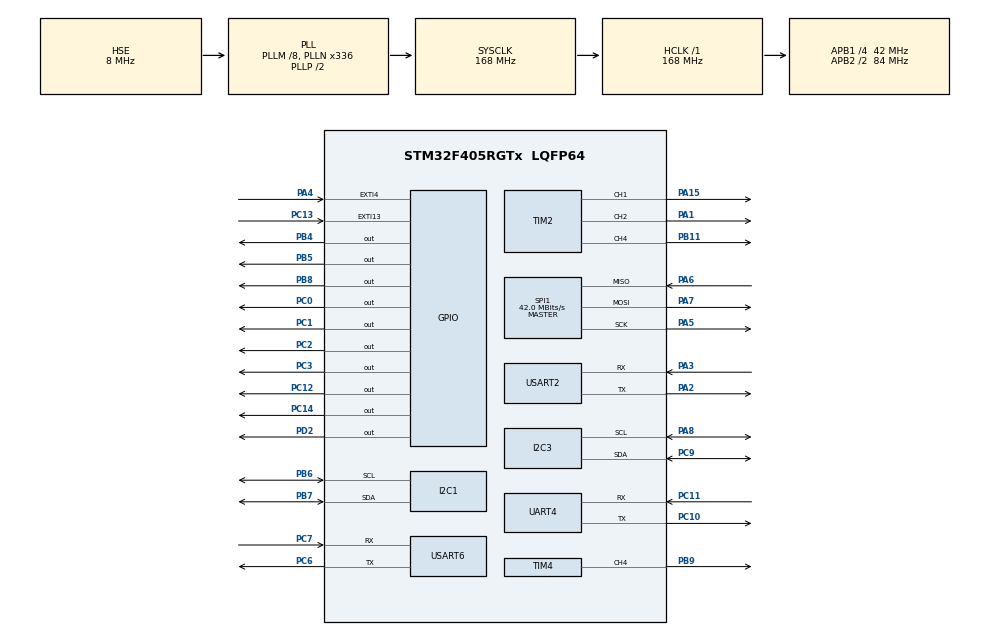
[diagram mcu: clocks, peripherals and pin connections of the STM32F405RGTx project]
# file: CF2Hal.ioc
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Mcu.Family=STM32F4
Mcu.Name=STM32F405RGTx
Mcu.Package=LQFP64
NVIC.PriorityGroup=NVIC_PRIORITYGROUP_4
PA1.Signal=S_TIM2_CH2
PA13.Mode=Trace_Asynchronous_SW
PA13.Signal=SYS_JTMS-SWDIO
PA14.Mode=Trace_Asynchronous_SW
PA14.Signal=SYS_JTCK-SWCLK
PA15.Signal=S_TIM2_CH1_ETR
PA2.Mode=Asynchronous
PA2.Signal=USART2_TX
PA3.Mode=Asynchronous
PA3.Signal=USART2_RX
PA4.Signal=GPXTI4
PA5.Mode=Full_Duplex_Master
PA5.Signal=SPI1_SCK
PA6.Mode=Full_Duplex_Master
PA6.Signal=SPI1_MISO
PA7.Mode=Full_Duplex_Master
PA7.Signal=SPI1_MOSI
PA8.Mode=I2C
PA8.Signal=I2C3_SCL
PB11.Signal=S_TIM2_CH4
PB3.Mode=Trace_Asynchronous_SW
PB3.Signal=SYS_JTDO-SWO
PB4.Signal=GPIO_Output
PB5.Signal=GPIO_Output
PB6.Mode=I2C
PB6.Signal=I2C1_SCL
PB7.Mode=I2C
PB7.Signal=I2C1_SDA
PB8.Signal=GPIO_Output
PB9.Signal=S_TIM4_CH4
PC0.Signal=GPIO_Output
PC1.Signal=GPIO_Output
PC10.Mode=Asynchronous
PC10.Signal=UART4_TX
PC11.Mode=Asynchronous
PC11.Signal=UART4_RX
PC12.Signal=GPIO_Output
PC13-ANTI_TAMP.Signal=GPXTI13
PC14-OSC32_IN.Signal=GPIO_Output
PC2.Signal=GPIO_Output
PC3.Signal=GPIO_Output
PC6.Mode=Asynchronous
PC6.Signal=USART6_TX
PC7.Mode=Asynchronous
PC7.Signal=USART6_RX
PC9.Mode=I2C
PC9.Signal=I2C3_SDA
PD2.Signal=GPIO_Output
PH0-OSC_IN.Mode=HSE-External-Oscillator
PH0-OSC_IN.Signal=RCC_OSC_IN
PH1-OSC_OUT.Mode=HSE-External-Oscillator
PH1-OSC_OUT.Signal=RCC_OSC_OUT
ProjectManager.HeapSize=0x16000
ProjectManager.StackSize=0x5000
ProjectManager.TargetToolchain=Makefile
RCC.48MHZClocksFreq_Value=84000000
RCC.AHBFreq_Value=168000000
RCC.APB1CLKDivider=RCC_HCLK_DIV4
RCC.APB1Freq_Value=42000000
RCC.APB1TimFreq_Value=84000000
RCC.APB2CLKDivider=RCC_HCLK_DIV2
RCC.APB2Freq_Value=84000000
RCC.APB2TimFreq_Value=168000000
RCC.CortexFreq_Value=21000000
RCC.Cortex_Div=SYSTICK_CLKSOURCE_HCLK_DIV8
RCC.HCLKFreq_Value=168000000
RCC.HSE_VALUE=8000000
RCC.HSI_VALUE=16000000
RCC.LSE_VALUE=32768
RCC.PLLM=8
RCC.PLLN=336
RCC.PLLSourceVirtual=RCC_PLLSOURCE_HSE
RCC.SYSCLKFreq_VALUE=168000000
RCC.SYSCLKSource=RCC_SYSCLKSOURCE_PLLCLK
RCC.VCOOutputFreq_Value=336000000
SH.S_TIM2_CH1_ETR.0=TIM2_CH1,PWM Generation1 CH1
SH.S_TIM2_CH2.0=TIM2_CH2,PWM Generation2 CH2
SH.S_TIM2_CH4.0=TIM2_CH4,PWM Generation4 CH4
SH.S_TIM4_CH4.0=TIM4_CH4,PWM Generation4 CH4
SPI1.BaudRatePrescaler=SPI_BAUDRATEPRESCALER_2
SPI1.CalculateBaudRate=42.0 MBits/s
SPI1.Direction=SPI_DIRECTION_2LINES
SPI1.Mode=SPI_MODE_MASTER
SPI1.VirtualType=VM_MASTER
TIM2.Channel-PWM\ Generation1\ CH1=TIM_CHANNEL_1
TIM2.Channel-PWM\ Generation2\ CH2=TIM_CHANNEL_2
TIM2.Channel-PWM\ Generation4\ CH4=TIM_CHANNEL_4
TIM4.Channel-PWM\ Generation4\ CH4=TIM_CHANNEL_4
UART4.VirtualMode=Asynchronous
USART2.VirtualMode=VM_ASYNC
USART6.VirtualMode=VM_ASYNC
board=custom

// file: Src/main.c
/**
  ******************************************************************************
  * @file           : main.c
  * @brief          : Main program body
  ******************************************************************************
  ** This notice applies to any and all portions of this file
  * that are not between comment pairs USER CODE BEGIN and
  * USER CODE END. Other portions of this file, whether
  * inserted by the user or by software development tools
  * are owned by their respective copyright owners.
  *
  * COPYRIGHT(c) 2019 STMicroelectronics
  *
  * Redistribution and use in source and binary forms, with or without modification,
  * are permitted provided that the following conditions are met:
  *   1. Redistributions of source code must retain the above copyright notice,
  *      this list of conditions and the following disclaimer.
  *   2. Redistributions in binary form must reproduce the above copyright notice,
  *      this list of conditions and the following disclaimer in the documentation
  *      and/or other materials provided with the distribution.
  *   3. Neither the name of STMicroelectronics nor the names of its contributors
  *      may be used to endorse or promote products derived from this software
  *      without specific prior written permission.
  *
  * THIS SOFTWARE IS PROVIDED BY THE COPYRIGHT HOLDERS AND CONTRIBUTORS "AS IS"
  * AND ANY EXPRESS OR IMPLIED WARRANTIES, INCLUDING, BUT NOT LIMITED TO, THE
  * IMPLIED WARRANTIES OF MERCHANTABILITY AND FITNESS FOR A PARTICULAR PURPOSE ARE
  * DISCLAIMED. IN NO EVENT SHALL THE COPYRIGHT HOLDER OR CONTRIBUTORS BE LIABLE
  * FOR ANY DIRECT, INDIRECT, INCIDENTAL, SPECIAL, EXEMPLARY, OR CONSEQUENTIAL
  * DAMAGES (INCLUDING, BUT NOT LIMITED TO, PROCUREMENT OF SUBSTITUTE GOODS OR
  * SERVICES; LOSS OF USE, DATA, OR PROFITS; OR BUSINESS INTERRUPTION) HOWEVER
  * CAUSED AND ON ANY THEORY OF LIABILITY, WHETHER IN CONTRACT, STRICT LIABILITY,
  * OR TORT (INCLUDING NEGLIGENCE OR OTHERWISE) ARISING IN ANY WAY OUT OF THE USE
  * OF THIS SOFTWARE, EVEN IF ADVISED OF THE POSSIBILITY OF SUCH DAMAGE.
  *
  ******************************************************************************
  */
#include "main.h"
#include "stm32f4xx_hal.h"

I2C_HandleTypeDef hi2c1;
I2C_HandleTypeDef hi2c3;

SPI_HandleTypeDef hspi1;

TIM_HandleTypeDef htim2;
TIM_HandleTypeDef htim4;

UART_HandleTypeDef huart4;
UART_HandleTypeDef huart2;
UART_HandleTypeDef huart6;

/* USER CODE BEGIN PV */
/* Private variables ---------------------------------------------------------*/

/* USER CODE END PV */

void SystemClock_Config(void);
static void MX_GPIO_Init(void);
static void MX_TIM2_Init(void);
static void MX_TIM4_Init(void);
static void MX_I2C1_Init(void);
static void MX_I2C3_Init(void);
static void MX_USART6_UART_Init(void);
static void MX_UART4_Init(void);
static void MX_USART2_UART_Init(void);
static void MX_SPI1_Init(void);

void HAL_TIM_MspPostInit(TIM_HandleTypeDef *htim);

/* USER CODE BEGIN PFP */
/* Private function prototypes -----------------------------------------------*/

/* USER CODE END PFP */

/* USER CODE BEGIN 0 */

void fsw_main(void);

/* USER CODE END 0 */

int main(void)
{

  /* MCU Configuration----------------------------------------------------------*/

  /* Reset of all peripherals, Initializes the Flash interface and the Systick. */
  HAL_Init();

  /* Configure the system clock */
  SystemClock_Config();

  /* Initialize all configured peripherals */
  MX_GPIO_Init();
  MX_TIM2_Init();
  MX_TIM4_Init();
  MX_I2C1_Init();
  MX_I2C3_Init();
  MX_USART6_UART_Init();
  MX_UART4_Init();
  MX_USART2_UART_Init();
  MX_SPI1_Init();

  /* USER CODE BEGIN 3 */
  fsw_main();

  /* USER CODE END 3 */

}

void SystemClock_Config(void)
{

  RCC_OscInitTypeDef RCC_OscInitStruct;
  RCC_ClkInitTypeDef RCC_ClkInitStruct;

    /**Configure the main internal regulator output voltage
    */
  __HAL_RCC_PWR_CLK_ENABLE();

  __HAL_PWR_VOLTAGESCALING_CONFIG(PWR_REGULATOR_VOLTAGE_SCALE1);

    /**Initializes the CPU, AHB and APB busses clocks
    */
  RCC_OscInitStruct.OscillatorType = RCC_OSCILLATORTYPE_HSE;
  RCC_OscInitStruct.HSEState = RCC_HSE_ON;
  RCC_OscInitStruct.PLL.PLLState = RCC_PLL_ON;
  RCC_OscInitStruct.PLL.PLLSource = RCC_PLLSOURCE_HSE;
  RCC_OscInitStruct.PLL.PLLM = 8;
  RCC_OscInitStruct.PLL.PLLN = 336;
  RCC_OscInitStruct.PLL.PLLP = RCC_PLLP_DIV2;
  RCC_OscInitStruct.PLL.PLLQ = 4;
  if (HAL_RCC_OscConfig(&RCC_OscInitStruct) != HAL_OK)
  {
    _Error_Handler(__FILE__, __LINE__);
  }

    /**Initializes the CPU, AHB and APB busses clocks
    */
  RCC_ClkInitStruct.ClockType = RCC_CLOCKTYPE_HCLK|RCC_CLOCKTYPE_SYSCLK
                              |RCC_CLOCKTYPE_PCLK1|RCC_CLOCKTYPE_PCLK2;
  RCC_ClkInitStruct.SYSCLKSource = RCC_SYSCLKSOURCE_PLLCLK;
  RCC_ClkInitStruct.AHBCLKDivider = RCC_SYSCLK_DIV1;
  RCC_ClkInitStruct.APB1CLKDivider = RCC_HCLK_DIV4;
  RCC_ClkInitStruct.APB2CLKDivider = RCC_HCLK_DIV2;

  if (HAL_RCC_ClockConfig(&RCC_ClkInitStruct, FLASH_LATENCY_5) != HAL_OK)
  {
    _Error_Handler(__FILE__, __LINE__);
  }

    /**Configure the Systick interrupt time
    */
  HAL_SYSTICK_Config(HAL_RCC_GetHCLKFreq()/8000);

    /**Configure the Systick
    */
  HAL_SYSTICK_CLKSourceConfig(SYSTICK_CLKSOURCE_HCLK_DIV8);

  /* SysTick_IRQn interrupt configuration */
  HAL_NVIC_SetPriority(SysTick_IRQn, 0, 0);
}

/* I2C1 init function */
static void MX_I2C1_Init(void)
{

  hi2c1.Instance = I2C1;
  hi2c1.Init.ClockSpeed = 100000;
  hi2c1.Init.DutyCycle = I2C_DUTYCYCLE_2;
  hi2c1.Init.OwnAddress1 = 0;
  hi2c1.Init.AddressingMode = I2C_ADDRESSINGMODE_7BIT;
  hi2c1.Init.DualAddressMode = I2C_DUALADDRESS_DISABLE;
  hi2c1.Init.OwnAddress2 = 0;
  hi2c1.Init.GeneralCallMode = I2C_GENERALCALL_DISABLE;
  hi2c1.Init.NoStretchMode = I2C_NOSTRETCH_DISABLE;
  if (HAL_I2C_Init(&hi2c1) != HAL_OK)
  {
    _Error_Handler(__FILE__, __LINE__);
  }

}

/* I2C3 init function */
static void MX_I2C3_Init(void)
{

  hi2c3.Instance = I2C3;
  hi2c3.Init.ClockSpeed = 100000;
  hi2c3.Init.DutyCycle = I2C_DUTYCYCLE_2;
  hi2c3.Init.OwnAddress1 = 0;
  hi2c3.Init.AddressingMode = I2C_ADDRESSINGMODE_7BIT;
  hi2c3.Init.DualAddressMode = I2C_DUALADDRESS_DISABLE;
  hi2c3.Init.OwnAddress2 = 0;
  hi2c3.Init.GeneralCallMode = I2C_GENERALCALL_DISABLE;
  hi2c3.Init.NoStretchMode = I2C_NOSTRETCH_DISABLE;
  if (HAL_I2C_Init(&hi2c3) != HAL_OK)
  {
    _Error_Handler(__FILE__, __LINE__);
  }

}

/* SPI1 init function */
static void MX_SPI1_Init(void)
{

  /* SPI1 parameter configuration*/
  hspi1.Instance = SPI1;
  hspi1.Init.Mode = SPI_MODE_MASTER;
  hspi1.Init.Direction = SPI_DIRECTION_2LINES;
  hspi1.Init.DataSize = SPI_DATASIZE_8BIT;
  hspi1.Init.CLKPolarity = SPI_POLARITY_LOW;
  hspi1.Init.CLKPhase = SPI_PHASE_1EDGE;
  hspi1.Init.NSS = SPI_NSS_SOFT;
  hspi1.Init.BaudRatePrescaler = SPI_BAUDRATEPRESCALER_2;
  hspi1.Init.FirstBit = SPI_FIRSTBIT_MSB;
  hspi1.Init.TIMode = SPI_TIMODE_DISABLE;
  hspi1.Init.CRCCalculation = SPI_CRCCALCULATION_DISABLE;
  hspi1.Init.CRCPolynomial = 10;
  if (HAL_SPI_Init(&hspi1) != HAL_OK)
  {
    _Error_Handler(__FILE__, __LINE__);
  }

}

/* TIM2 init function */
static void MX_TIM2_Init(void)
{

  TIM_MasterConfigTypeDef sMasterConfig;
  TIM_OC_InitTypeDef sConfigOC;

  htim2.Instance = TIM2;
  htim2.Init.Prescaler = 0;
  htim2.Init.CounterMode = TIM_COUNTERMODE_UP;
  htim2.Init.Period = 0;
  htim2.Init.ClockDivision = TIM_CLOCKDIVISION_DIV1;
  if (HAL_TIM_PWM_Init(&htim2) != HAL_OK)
  {
    _Error_Handler(__FILE__, __LINE__);
  }

  sMasterConfig.MasterOutputTrigger = TIM_TRGO_RESET;
  sMasterConfig.MasterSlaveMode = TIM_MASTERSLAVEMODE_DISABLE;
  if (HAL_TIMEx_MasterConfigSynchronization(&htim2, &sMasterConfig) != HAL_OK)
  {
    _Error_Handler(__FILE__, __LINE__);
  }

  sConfigOC.OCMode = TIM_OCMODE_PWM1;
  sConfigOC.Pulse = 0;
  sConfigOC.OCPolarity = TIM_OCPOLARITY_HIGH;
  sConfigOC.OCFastMode = TIM_OCFAST_DISABLE;
  if (HAL_TIM_PWM_ConfigChannel(&htim2, &sConfigOC, TIM_CHANNEL_1) != HAL_OK)
  {
    _Error_Handler(__FILE__, __LINE__);
  }

  if (HAL_TIM_PWM_ConfigChannel(&htim2, &sConfigOC, TIM_CHANNEL_2) != HAL_OK)
  {
    _Error_Handler(__FILE__, __LINE__);
  }

  if (HAL_TIM_PWM_ConfigChannel(&htim2, &sConfigOC, TIM_CHANNEL_4) != HAL_OK)
  {
    _Error_Handler(__FILE__, __LINE__);
  }

  HAL_TIM_MspPostInit(&htim2);

}

/* TIM4 init function */
static void MX_TIM4_Init(void)
{

  TIM_MasterConfigTypeDef sMasterConfig;
  TIM_OC_InitTypeDef sConfigOC;

  htim4.Instance = TIM4;
  htim4.Init.Prescaler = 0;
  htim4.Init.CounterMode = TIM_COUNTERMODE_UP;
  htim4.Init.Period = 0;
  htim4.Init.ClockDivision = TIM_CLOCKDIVISION_DIV1;
  if (HAL_TIM_PWM_Init(&htim4) != HAL_OK)
  {
    _Error_Handler(__FILE__, __LINE__);
  }

  sMasterConfig.MasterOutputTrigger = TIM_TRGO_RESET;
  sMasterConfig.MasterSlaveMode = TIM_MASTERSLAVEMODE_DISABLE;
  if (HAL_TIMEx_MasterConfigSynchronization(&htim4, &sMasterConfig) != HAL_OK)
  {
    _Error_Handler(__FILE__, __LINE__);
  }

  sConfigOC.OCMode = TIM_OCMODE_PWM1;
  sConfigOC.Pulse = 0;
  sConfigOC.OCPolarity = TIM_OCPOLARITY_HIGH;
  sConfigOC.OCFastMode = TIM_OCFAST_DISABLE;
  if (HAL_TIM_PWM_ConfigChannel(&htim4, &sConfigOC, TIM_CHANNEL_4) != HAL_OK)
  {
    _Error_Handler(__FILE__, __LINE__);
  }

  HAL_TIM_MspPostInit(&htim4);

}

/* UART4 init function */
static void MX_UART4_Init(void)
{

  huart4.Instance = UART4;
  huart4.Init.BaudRate = 115200;
  huart4.Init.WordLength = UART_WORDLENGTH_8B;
  huart4.Init.StopBits = UART_STOPBITS_1;
  huart4.Init.Parity = UART_PARITY_NONE;
  huart4.Init.Mode = UART_MODE_TX_RX;
  huart4.Init.HwFlowCtl = UART_HWCONTROL_NONE;
  huart4.Init.OverSampling = UART_OVERSAMPLING_16;
  if (HAL_UART_Init(&huart4) != HAL_OK)
  {
    _Error_Handler(__FILE__, __LINE__);
  }

}

/* USART2 init function */
static void MX_USART2_UART_Init(void)
{

  huart2.Instance = USART2;
  huart2.Init.BaudRate = 115200;
  huart2.Init.WordLength = UART_WORDLENGTH_8B;
  huart2.Init.StopBits = UART_STOPBITS_1;
  huart2.Init.Parity = UART_PARITY_NONE;
  huart2.Init.Mode = UART_MODE_TX_RX;
  huart2.Init.HwFlowCtl = UART_HWCONTROL_NONE;
  huart2.Init.OverSampling = UART_OVERSAMPLING_16;
  if (HAL_UART_Init(&huart2) != HAL_OK)
  {
    _Error_Handler(__FILE__, __LINE__);
  }

}

/* USART6 init function */
static void MX_USART6_UART_Init(void)
{

  huart6.Instance = USART6;
  huart6.Init.BaudRate = 115200;
  huart6.Init.WordLength = UART_WORDLENGTH_8B;
  huart6.Init.StopBits = UART_STOPBITS_1;
  huart6.Init.Parity = UART_PARITY_NONE;
  huart6.Init.Mode = UART_MODE_TX_RX;
  huart6.Init.HwFlowCtl = UART_HWCONTROL_NONE;
  huart6.Init.OverSampling = UART_OVERSAMPLING_16;
  if (HAL_UART_Init(&huart6) != HAL_OK)
  {
    _Error_Handler(__FILE__, __LINE__);
  }

}

/** Configure pins as
        * Analog
        * Input
        * Output
        * EVENT_OUT
        * EXTI
*/
static void MX_GPIO_Init(void)
{

  GPIO_InitTypeDef GPIO_InitStruct;

  /* GPIO Ports Clock Enable */
  __HAL_RCC_GPIOC_CLK_ENABLE();
  __HAL_RCC_GPIOH_CLK_ENABLE();
  __HAL_RCC_GPIOA_CLK_ENABLE();
  __HAL_RCC_GPIOB_CLK_ENABLE();
  __HAL_RCC_GPIOD_CLK_ENABLE();

  /*Configure GPIO pin Output Level */
  HAL_GPIO_WritePin(GPIOC, GPIO_PIN_14|GPIO_PIN_0|GPIO_PIN_1|GPIO_PIN_2
                          |GPIO_PIN_3|GPIO_PIN_12, GPIO_PIN_RESET);

  /*Configure GPIO pin Output Level */
  HAL_GPIO_WritePin(GPIOD, GPIO_PIN_2, GPIO_PIN_RESET);

  /*Configure GPIO pin Output Level */
  HAL_GPIO_WritePin(GPIOB, GPIO_PIN_4|GPIO_PIN_5|GPIO_PIN_8, GPIO_PIN_RESET);

  /*Configure GPIO pin : PC13 */
  GPIO_InitStruct.Pin = GPIO_PIN_13;
  GPIO_InitStruct.Mode = GPIO_MODE_IT_RISING;
  GPIO_InitStruct.Pull = GPIO_NOPULL;
  HAL_GPIO_Init(GPIOC, &GPIO_InitStruct);

  /*Configure GPIO pins : PC14 PC0 PC1 PC2
                           PC3 PC12 */
  GPIO_InitStruct.Pin = GPIO_PIN_14|GPIO_PIN_0|GPIO_PIN_1|GPIO_PIN_2
                          |GPIO_PIN_3|GPIO_PIN_12;
  GPIO_InitStruct.Mode = GPIO_MODE_OUTPUT_PP;
  GPIO_InitStruct.Pull = GPIO_NOPULL;
  GPIO_InitStruct.Speed = GPIO_SPEED_FREQ_LOW;
  HAL_GPIO_Init(GPIOC, &GPIO_InitStruct);

  /*Configure GPIO pin : PA4 */
  GPIO_InitStruct.Pin = GPIO_PIN_4;
  GPIO_InitStruct.Mode = GPIO_MODE_IT_RISING;
  GPIO_InitStruct.Pull = GPIO_NOPULL;
  HAL_GPIO_Init(GPIOA, &GPIO_InitStruct);

  /*Configure GPIO pin : PD2 */
  GPIO_InitStruct.Pin = GPIO_PIN_2;
  GPIO_InitStruct.Mode = GPIO_MODE_OUTPUT_PP;
  GPIO_InitStruct.Pull = GPIO_NOPULL;
  GPIO_InitStruct.Speed = GPIO_SPEED_FREQ_LOW;
  HAL_GPIO_Init(GPIOD, &GPIO_InitStruct);

  /*Configure GPIO pins : PB4 PB5 PB8 */
  GPIO_InitStruct.Pin = GPIO_PIN_4|GPIO_PIN_5|GPIO_PIN_8;
  GPIO_InitStruct.Mode = GPIO_MODE_OUTPUT_PP;
  GPIO_InitStruct.Pull = GPIO_NOPULL;
  GPIO_InitStruct.Speed = GPIO_SPEED_FREQ_LOW;
  HAL_GPIO_Init(GPIOB, &GPIO_InitStruct);

}

void _Error_Handler(char *file, int line)
{
  while(1)
  {
  }
}

/************************ (C) COPYRIGHT STMicroelectronics *****END OF FILE****/
